# ATSAMS70J20B device description
Architecture: CORTEX-M7; Family: SAMS; Series: SAMS70
Registers are 32-bit, read-write, no defined reset value unless marked. A register's access mark holds for its fields unless they carry their own. Offsets are from the block's base; [hi:lo] are bit positions; {n}, {i} and the like mark numbered series.

## PMC — Power Management Controller
Instances: PMC 0x400E0600
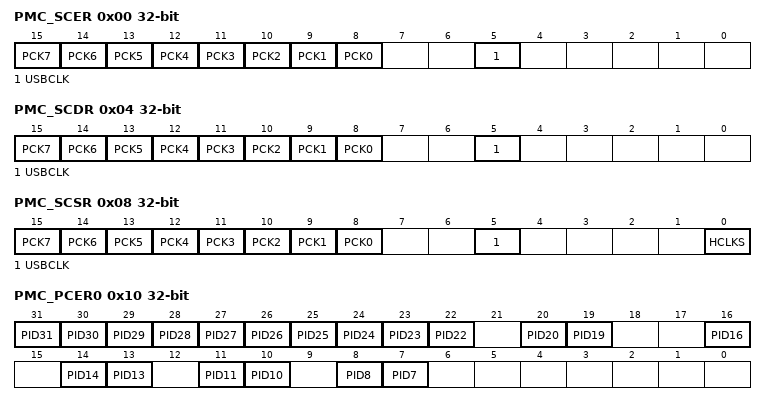
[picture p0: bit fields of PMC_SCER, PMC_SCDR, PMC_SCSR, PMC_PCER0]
0x00 PMC_SCER wo (atomic set of PMC_SCSR) — System Clock Enable Register
  [n+8] PCK{n} (n=0..7) — Programmable Clock {n} Output Enable
  [5] USBCLK — Enable USB FS Clock
0x04 PMC_SCDR wo (atomic clear of PMC_SCSR) — System Clock Disable Register
  [n+8] PCK{n} (n=0..7) — Programmable Clock {n} Output Disable
  [5] USBCLK — Disable USB FS Clock
0x08 PMC_SCSR ro — System Clock Status Register
  [n+8] PCK{n} (n=0..7) — Programmable Clock {n} Output Status
  [5] USBCLK — USB FS Clock Status
  [0] HCLKS — HCLK Status
0x10 PMC_PCER0 wo (atomic set of PMC_PCSR0) — Peripheral Clock Enable Register 0
  [n] PID{n} (n=22..31) — Peripheral Clock {n} Enable
  [20] PID20 — Peripheral Clock 20 Enable
  [19] PID19 — Peripheral Clock 19 Enable
  [16] PID16 — Peripheral Clock 16 Enable
  [14] PID14 — Peripheral Clock 14 Enable
  [13] PID13 — Peripheral Clock 13 Enable
  [11] PID11 — Peripheral Clock 11 Enable
  [10] PID10 — Peripheral Clock 10 Enable
  [8] PID8 — Peripheral Clock 8 Enable
  [7] PID7 — Peripheral Clock 7 Enable
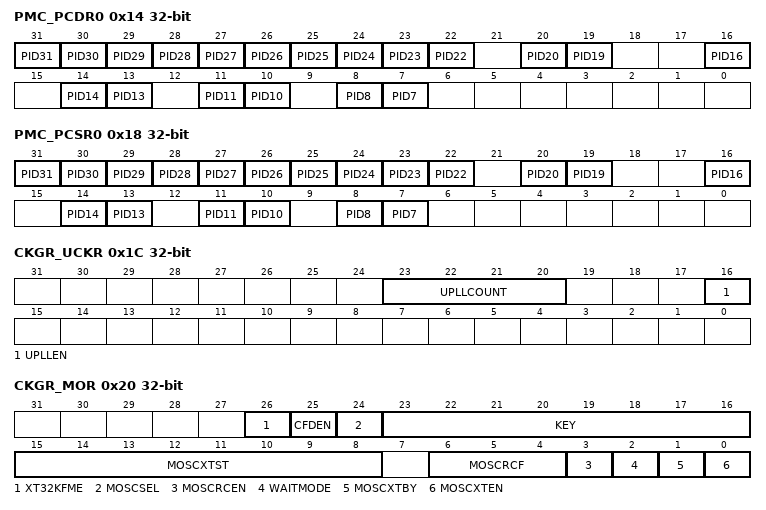
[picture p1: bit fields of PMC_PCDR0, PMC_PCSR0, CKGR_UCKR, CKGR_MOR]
0x14 PMC_PCDR0 wo (atomic clear of PMC_PCSR0) — Peripheral Clock Disable Register 0
  [n] PID{n} (n=22..31) — Peripheral Clock {n} Disable
  [20] PID20 — Peripheral Clock 20 Disable
  [19] PID19 — Peripheral Clock 19 Disable
  [16] PID16 — Peripheral Clock 16 Disable
  [14] PID14 — Peripheral Clock 14 Disable
  [13] PID13 — Peripheral Clock 13 Disable
  [11] PID11 — Peripheral Clock 11 Disable
  [10] PID10 — Peripheral Clock 10 Disable
  [8] PID8 — Peripheral Clock 8 Disable
  [7] PID7 — Peripheral Clock 7 Disable
0x18 PMC_PCSR0 ro — Peripheral Clock Status Register 0
  [n] PID{n} (n=22..31) — Peripheral Clock {n} Status
  [20] PID20 — Peripheral Clock 20 Status
  [19] PID19 — Peripheral Clock 19 Status
  [16] PID16 — Peripheral Clock 16 Status
  [14] PID14 — Peripheral Clock 14 Status
  [13] PID13 — Peripheral Clock 13 Status
  [11] PID11 — Peripheral Clock 11 Status
  [10] PID10 — Peripheral Clock 10 Status
  [8] PID8 — Peripheral Clock 8 Status
  [7] PID7 — Peripheral Clock 7 Status
0x1C CKGR_UCKR — UTMI Clock Register
  [23:20] UPLLCOUNT — UTMI PLL Start-up Time
  [16] UPLLEN — UTMI PLL Enable
0x20 CKGR_MOR — Main Oscillator Register
  [26] XT32KFME — 32.768 kHz Crystal Oscillator Frequency Monitoring Enable
  [25] CFDEN — Clock Failure Detector Enable
  [24] MOSCSEL — Main Clock Oscillator Selection
  [23:16] KEY — Write Access Password
    55=PASSWD (Writing any other value in this field aborts the write operation.Always reads as 0.)
  [15:8] MOSCXTST — Main Crystal Oscillator Startup Time
  [6:4] MOSCRCF — Main RC Oscillator Frequency Selection
    0=_4_MHz (The RC oscillator frequency is at 4 MHz); 1=_8_MHz (The RC oscillator frequency is at 8 MHz); 2=_12_MHz (The RC oscillator frequency is at 12 MHz)
  [3] MOSCRCEN — Main RC Oscillator Enable
  [2] WAITMODE — Wait Mode Command (Write-only)
  [1] MOSCXTBY — Main Crystal Oscillator Bypass
  [0] MOSCXTEN — Main Crystal Oscillator Enable
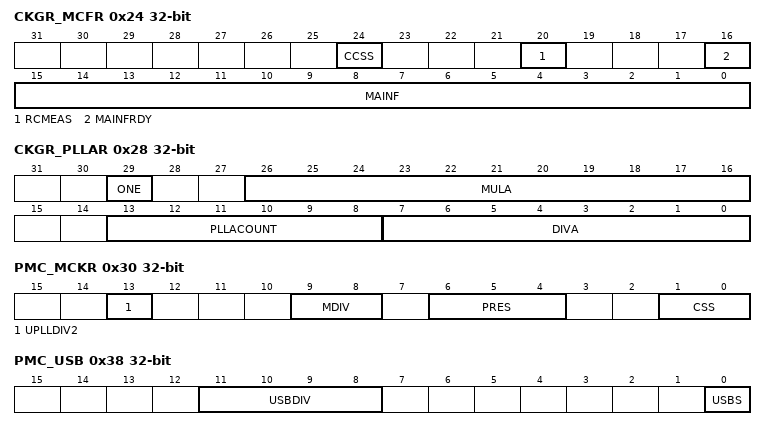
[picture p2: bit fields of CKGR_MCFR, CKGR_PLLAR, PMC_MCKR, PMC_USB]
0x24 CKGR_MCFR — Main Clock Frequency Register
  [24] CCSS — Counter Clock Source Selection
  [20] RCMEAS — RC Oscillator Frequency Measure (write-only)
  [16] MAINFRDY — Main Clock Frequency Measure Ready
  [15:0] MAINF — Main Clock Frequency
0x28 CKGR_PLLAR — PLLA Register
  [29] ONE — Must Be Set to 1
  [26:16] MULA — PLLA Multiplier
  [13:8] PLLACOUNT — PLLA Counter
  [7:0] DIVA — PLLA Front End Divider
    0=Divider output is 0 and PLLA is disabled; 1=BYPASS (Divider is bypassed (divide by 1) and PLLA is enabled.)
0x30 PMC_MCKR — Master Clock Register
  [13] UPLLDIV2 — UPLL Divider by 2
  [9:8] MDIV — Master Clock Division
    0=EQ_PCK (Master Clock is Prescaler Output Clock divided by 1.); 1=PCK_DIV2 (Master Clock is Prescaler Output Clock divided by 2.); 2=PCK_DIV4 (Master Clock is Prescaler Output Clock divided by 4.); 3=PCK_DIV3 (Master Clock is Prescaler Output Clock divided by 3.)
  [6:4] PRES — Processor Clock Prescaler
    0=CLK_1 (Selected clock); 1=CLK_2 (Selected clock divided by 2); 2=CLK_4 (Selected clock divided by 4); 3=CLK_8 (Selected clock divided by 8); 4=CLK_16 (Selected clock divided by 16); 5=CLK_32 (Selected clock divided by 32); 6=CLK_64 (Selected clock divided by 64); 7=CLK_3 (Selected clock divided by 3)
  [1:0] CSS — Master Clock Source Selection
    0=SLOW_CLK (Slow Clock is selected); 1=MAIN_CLK (Main Clock is selected); 2=PLLA_CLK (PLLA Clock is selected); 3=UPLL_CLK (Divided UPLL Clock is selected)
0x38 PMC_USB — USB Clock Register
  [11:8] USBDIV — Divider for USB_48M
  [0] USBS — USB Input Clock Selection
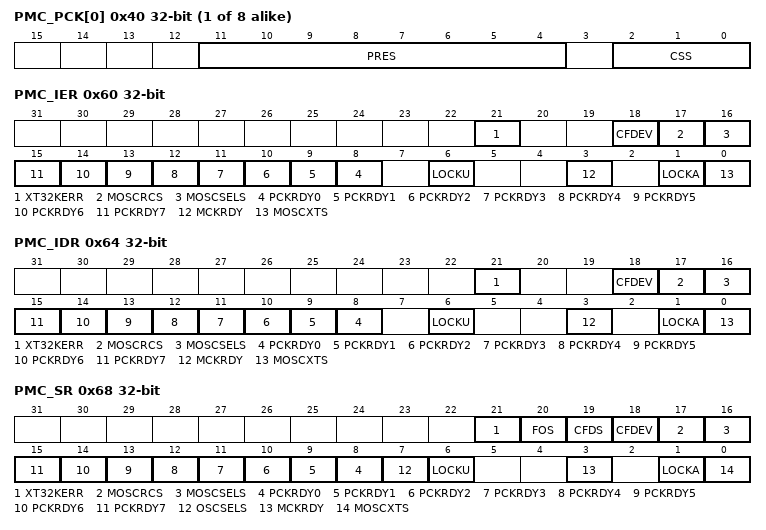
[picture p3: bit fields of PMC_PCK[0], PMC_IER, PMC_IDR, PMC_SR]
{0x40+4i} PMC_PCK[{i}] (i=0..7) — Programmable Clock Register
  [11:4] PRES — Programmable Clock Prescaler
  [2:0] CSS — Programmable Clock Source Selection
    0=SLOW_CLK (SLCK is selected); 1=MAIN_CLK (MAINCK is selected); 2=PLLA_CLK (PLLACK is selected); 3=UPLL_CLK (UPLLCKDIV is selected); 4=MCK (MCK is selected)
0x60 PMC_IER wo (atomic set of PMC_IMR) — Interrupt Enable Register
  [21] XT32KERR — 32.768 kHz Crystal Oscillator Error Interrupt Enable
  [18] CFDEV — Clock Failure Detector Event Interrupt Enable
  [17] MOSCRCS — Main RC Oscillator Status Interrupt Enable
  [16] MOSCSELS — Main Clock Source Oscillator Selection Status Interrupt Enable
  [n+8] PCKRDY{n} (n=0..7) — Programmable Clock Ready {n} Interrupt Enable
  [6] LOCKU — UTMI PLL Lock Interrupt Enable
  [3] MCKRDY — Master Clock Ready Interrupt Enable
  [1] LOCKA — PLLA Lock Interrupt Enable
  [0] MOSCXTS — Main Crystal Oscillator Status Interrupt Enable
0x64 PMC_IDR wo (atomic clear of PMC_IMR) — Interrupt Disable Register
  [21] XT32KERR — 32.768 kHz Crystal Oscillator Error Interrupt Disable
  [18] CFDEV — Clock Failure Detector Event Interrupt Disable
  [17] MOSCRCS — Main RC Status Interrupt Disable
  [16] MOSCSELS — Main Clock Source Oscillator Selection Status Interrupt Disable
  [n+8] PCKRDY{n} (n=0..7) — Programmable Clock Ready {n} Interrupt Disable
  [6] LOCKU — UTMI PLL Lock Interrupt Disable
  [3] MCKRDY — Master Clock Ready Interrupt Disable
  [1] LOCKA — PLLA Lock Interrupt Disable
  [0] MOSCXTS — Main Crystal Oscillator Status Interrupt Disable
0x68 PMC_SR ro — Status Register
  [21] XT32KERR — Slow Crystal Oscillator Error
  [20] FOS — Clock Failure Detector Fault Output Status
  [19] CFDS — Clock Failure Detector Status
  [18] CFDEV — Clock Failure Detector Event
  [17] MOSCRCS — Main RC Oscillator Status
  [16] MOSCSELS — Main Clock Source Oscillator Selection Status
  [n+8] PCKRDY{n} (n=0..7) — Programmable Clock Ready {n} Status
  [7] OSCSELS — Slow Clock Source Oscillator Selection
  [6] LOCKU — UTMI PLL Lock Status
  [3] MCKRDY — Master Clock Status
  [1] LOCKA — PLLA Lock Status
  [0] MOSCXTS — Main Crystal Oscillator Status
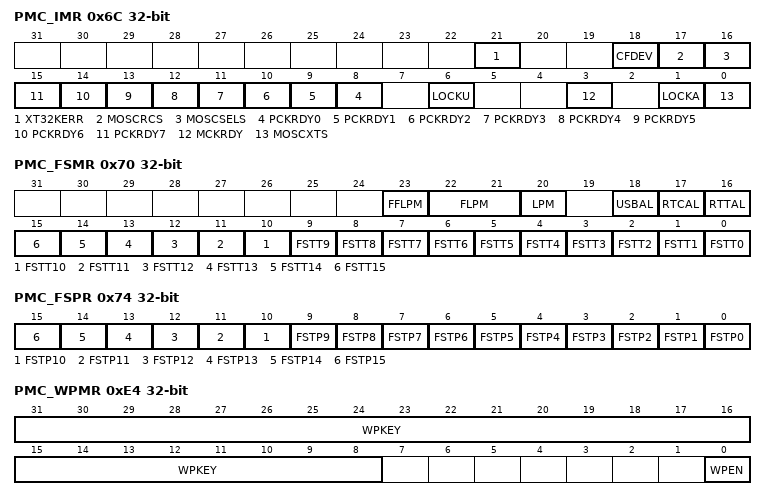
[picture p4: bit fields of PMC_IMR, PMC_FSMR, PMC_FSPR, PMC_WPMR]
0x6C PMC_IMR ro (atomic read) — Interrupt Mask Register
  [21] XT32KERR — 32.768 kHz Crystal Oscillator Error Interrupt Mask
  [18] CFDEV — Clock Failure Detector Event Interrupt Mask
  [17] MOSCRCS — Main RC Status Interrupt Mask
  [16] MOSCSELS — Main Clock Source Oscillator Selection Status Interrupt Mask
  [n+8] PCKRDY{n} (n=0..7) — Programmable Clock Ready {n} Interrupt Mask
  [6] LOCKU — UTMI PLL Lock Interrupt Mask
  [3] MCKRDY — Master Clock Ready Interrupt Mask
  [1] LOCKA — PLLA Lock Interrupt Mask
  [0] MOSCXTS — Main Crystal Oscillator Status Interrupt Mask
0x70 PMC_FSMR — Fast Startup Mode Register
  [23] FFLPM — Force Flash Low-power Mode
  [22:21] FLPM — Flash Low-power Mode
    0=FLASH_STANDBY (Flash is in Standby Mode when system enters Wait Mode); 1=FLASH_DEEP_POWERDOWN (Flash is in Deep-power-down mode when system enters Wait Mode); 2=FLASH_IDLE (Idle mode)
  [20] LPM — Low-power Mode
  [18] USBAL — USB Alarm Enable
  [17] RTCAL — RTC Alarm Enable
  [16] RTTAL — RTT Alarm Enable
  [n] FSTT{n} (n=0..15) — Fast Startup Input Enable {n}
0x74 PMC_FSPR — Fast Startup Polarity Register
  [n] FSTP{n} (n=0..15) — Fast Startup Input Polarity {n}
0x78 PMC_FOCR wo — Fault Output Clear Register
  [0] FOCLR — Fault Output Clear
0xE4 PMC_WPMR — Write Protection Mode Register
  [31:8] WPKEY — Write Protection Key
    0x504D43=PASSWD (Writing any other value in this field aborts the write operation of the WPEN bit. Always reads as 0.)
  [0] WPEN — Write Protection Enable
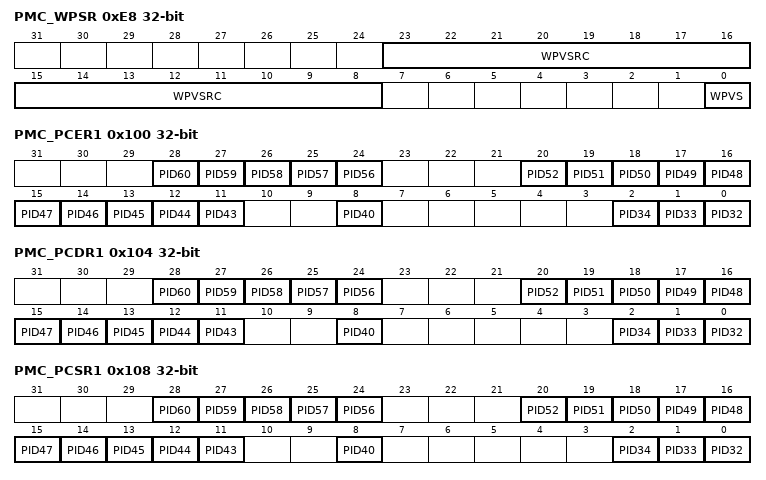
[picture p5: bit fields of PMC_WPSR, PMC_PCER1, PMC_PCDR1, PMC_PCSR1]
0xE8 PMC_WPSR ro — Write Protection Status Register
  [23:8] WPVSRC — Write Protection Violation Source
  [0] WPVS — Write Protection Violation Status
0x100 PMC_PCER1 wo (atomic set of PMC_PCSR1) — Peripheral Clock Enable Register 1
  [n-32] PID{n} (n=56..60) — Peripheral Clock {n} Enable
  [n-32] PID{n} (n=43..52) — Peripheral Clock {n} Enable
  [8] PID40 — Peripheral Clock 40 Enable
  [2] PID34 — Peripheral Clock 34 Enable
  [1] PID33 — Peripheral Clock 33 Enable
  [0] PID32 — Peripheral Clock 32 Enable
0x104 PMC_PCDR1 wo (atomic clear of PMC_PCSR1) — Peripheral Clock Disable Register 1
  [n-32] PID{n} (n=56..60) — Peripheral Clock {n} Disable
  [n-32] PID{n} (n=43..52) — Peripheral Clock {n} Disable
  [8] PID40 — Peripheral Clock 40 Disable
  [2] PID34 — Peripheral Clock 34 Disable
  [1] PID33 — Peripheral Clock 33 Disable
  [0] PID32 — Peripheral Clock 32 Disable
0x108 PMC_PCSR1 ro — Peripheral Clock Status Register 1
  [n-32] PID{n} (n=56..60) — Peripheral Clock {n} Status
  [n-32] PID{n} (n=43..52) — Peripheral Clock {n} Status
  [8] PID40 — Peripheral Clock 40 Status
  [2] PID34 — Peripheral Clock 34 Status
  [1] PID33 — Peripheral Clock 33 Status
  [0] PID32 — Peripheral Clock 32 Status
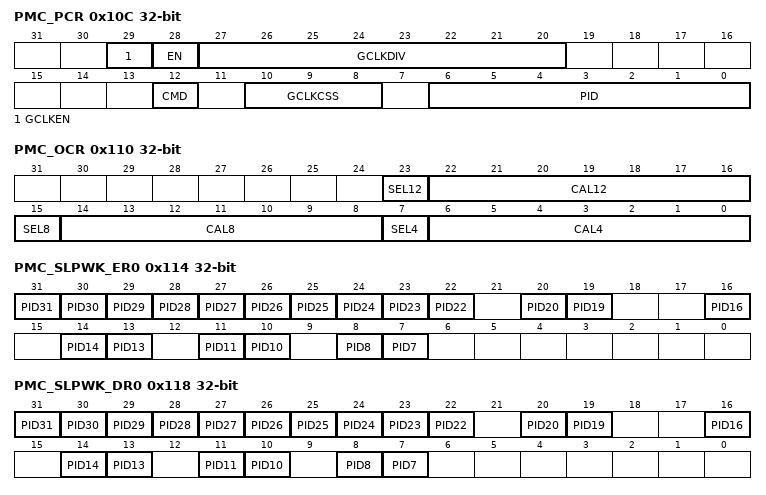
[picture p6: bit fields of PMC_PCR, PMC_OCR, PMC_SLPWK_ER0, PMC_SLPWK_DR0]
0x10C PMC_PCR — Peripheral Control Register
  [29] GCLKEN — Generic Clock Enable
  [28] EN — Enable
  [27:20] GCLKDIV — Generic Clock Division Ratio
  [12] CMD — Command
  [10:8] GCLKCSS — Generic Clock Source Selection
    0=SLOW_CLK (Slow clock is selected); 1=MAIN_CLK (Main clock is selected); 2=PLLA_CLK (PLLACK is selected); 3=UPLL_CLK (UPLL Clock is selected); 4=MCK_CLK (Master Clock is selected)
  [6:0] PID — Peripheral ID
0x110 PMC_OCR — Oscillator Calibration Register
  [23] SEL12 — Selection of Main RC Oscillator Calibration Bits for 12 MHz
  [22:16] CAL12 — Main RC Oscillator Calibration Bits for 12 MHz
  [15] SEL8 — Selection of Main RC Oscillator Calibration Bits for 8 MHz
  [14:8] CAL8 — Main RC Oscillator Calibration Bits for 8 MHz
  [7] SEL4 — Selection of Main RC Oscillator Calibration Bits for 4 MHz
  [6:0] CAL4 — Main RC Oscillator Calibration Bits for 4 MHz
0x114 PMC_SLPWK_ER0 wo (atomic set of PMC_SLPWK_SR0) — SleepWalking Enable Register 0
  [n] PID{n} (n=22..31) — Peripheral {n} SleepWalking Enable
  [20] PID20 — Peripheral 20 SleepWalking Enable
  [19] PID19 — Peripheral 19 SleepWalking Enable
  [16] PID16 — Peripheral 16 SleepWalking Enable
  [14] PID14 — Peripheral 14 SleepWalking Enable
  [13] PID13 — Peripheral 13 SleepWalking Enable
  [11] PID11 — Peripheral 11 SleepWalking Enable
  [10] PID10 — Peripheral 10 SleepWalking Enable
  [8] PID8 — Peripheral 8 SleepWalking Enable
  [7] PID7 — Peripheral 7 SleepWalking Enable
0x118 PMC_SLPWK_DR0 wo (atomic clear of PMC_SLPWK_SR0) — SleepWalking Disable Register 0
  [n] PID{n} (n=22..31) — Peripheral {n} SleepWalking Disable
  [20] PID20 — Peripheral 20 SleepWalking Disable
  [19] PID19 — Peripheral 19 SleepWalking Disable
  [16] PID16 — Peripheral 16 SleepWalking Disable
  [14] PID14 — Peripheral 14 SleepWalking Disable
  [13] PID13 — Peripheral 13 SleepWalking Disable
  [11] PID11 — Peripheral 11 SleepWalking Disable
  [10] PID10 — Peripheral 10 SleepWalking Disable
  [8] PID8 — Peripheral 8 SleepWalking Disable
  [7] PID7 — Peripheral 7 SleepWalking Disable
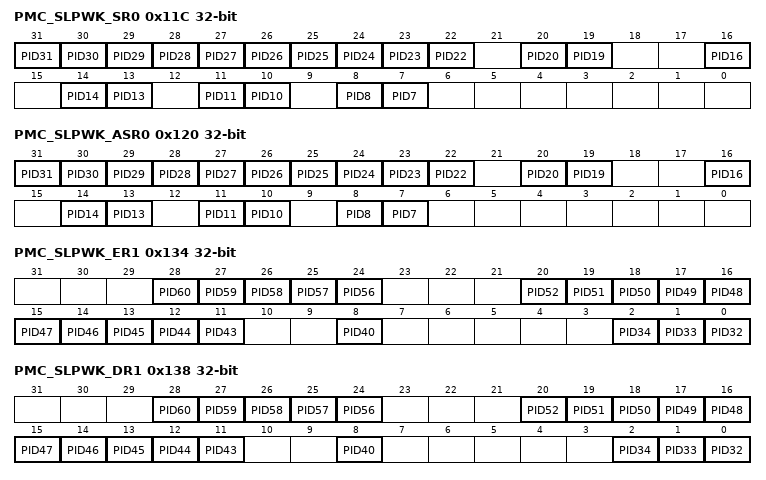
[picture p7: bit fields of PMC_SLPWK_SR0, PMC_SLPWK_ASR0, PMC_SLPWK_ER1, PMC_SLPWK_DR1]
0x11C PMC_SLPWK_SR0 ro — SleepWalking Status Register 0
  [n] PID{n} (n=22..31) — Peripheral {n} SleepWalking Status
  [20] PID20 — Peripheral 20 SleepWalking Status
  [19] PID19 — Peripheral 19 SleepWalking Status
  [16] PID16 — Peripheral 16 SleepWalking Status
  [14] PID14 — Peripheral 14 SleepWalking Status
  [13] PID13 — Peripheral 13 SleepWalking Status
  [11] PID11 — Peripheral 11 SleepWalking Status
  [10] PID10 — Peripheral 10 SleepWalking Status
  [8] PID8 — Peripheral 8 SleepWalking Status
  [7] PID7 — Peripheral 7 SleepWalking Status
0x120 PMC_SLPWK_ASR0 ro — SleepWalking Activity Status Register 0
  [n] PID{n} (n=22..31) — Peripheral {n} Activity Status
  [20] PID20 — Peripheral 20 Activity Status
  [19] PID19 — Peripheral 19 Activity Status
  [16] PID16 — Peripheral 16 Activity Status
  [14] PID14 — Peripheral 14 Activity Status
  [13] PID13 — Peripheral 13 Activity Status
  [11] PID11 — Peripheral 11 Activity Status
  [10] PID10 — Peripheral 10 Activity Status
  [8] PID8 — Peripheral 8 Activity Status
  [7] PID7 — Peripheral 7 Activity Status
0x130 PMC_PMMR — PLL Maximum Multiplier Value Register
  [10:0] PLLA_MMAX — PLLA Maximum Allowed Multiplier Value
0x134 PMC_SLPWK_ER1 wo (atomic set of PMC_SLPWK_SR1) — SleepWalking Enable Register 1
  [n-32] PID{n} (n=56..60) — Peripheral {n} SleepWalking Enable
  [n-32] PID{n} (n=43..52) — Peripheral {n} SleepWalking Enable
  [8] PID40 — Peripheral 40 SleepWalking Enable
  [2] PID34 — Peripheral 34 SleepWalking Enable
  [1] PID33 — Peripheral 33 SleepWalking Enable
  [0] PID32 — Peripheral 32 SleepWalking Enable
0x138 PMC_SLPWK_DR1 wo (atomic clear of PMC_SLPWK_SR1) — SleepWalking Disable Register 1
  [n-32] PID{n} (n=56..60) — Peripheral {n} SleepWalking Disable
  [n-32] PID{n} (n=43..52) — Peripheral {n} SleepWalking Disable
  [8] PID40 — Peripheral 40 SleepWalking Disable
  [2] PID34 — Peripheral 34 SleepWalking Disable
  [1] PID33 — Peripheral 33 SleepWalking Disable
  [0] PID32 — Peripheral 32 SleepWalking Disable
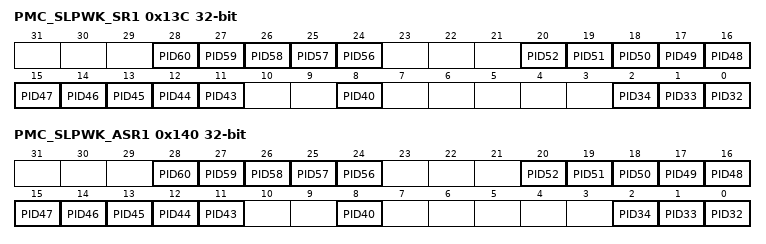
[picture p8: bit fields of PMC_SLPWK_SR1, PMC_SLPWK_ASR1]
0x13C PMC_SLPWK_SR1 ro — SleepWalking Status Register 1
  [n-32] PID{n} (n=56..60) — Peripheral {n} SleepWalking Status
  [n-32] PID{n} (n=43..52) — Peripheral {n} SleepWalking Status
  [8] PID40 — Peripheral 40 SleepWalking Status
  [2] PID34 — Peripheral 34 SleepWalking Status
  [1] PID33 — Peripheral 33 SleepWalking Status
  [0] PID32 — Peripheral 32 SleepWalking Status
0x140 PMC_SLPWK_ASR1 ro — SleepWalking Activity Status Register 1
  [n-32] PID{n} (n=56..60) — Peripheral {n} Activity Status
  [n-32] PID{n} (n=43..52) — Peripheral {n} Activity Status
  [8] PID40 — Peripheral 40 Activity Status
  [2] PID34 — Peripheral 34 Activity Status
  [1] PID33 — Peripheral 33 Activity Status
  [0] PID32 — Peripheral 32 Activity Status
0x144 PMC_SLPWK_AIPR ro — SleepWalking Activity In Progress Register
  [0] AIP — Activity In Progress

## Notices in the file
Copyright (c) 2017 Microchip Technology Inc.
SPDX-License-Identifier: Apache-2.0
Licensed under the Apache License, Version 2.0 (the "License");
you may not use this file except in compliance with the License.
You may obtain a copy of the License at
http://www.apache.org/licenses/LICENSE-2.0
Unless required by applicable law or agreed to in writing, software
distributed under the License is distributed on an "AS IS" BASIS,
WITHOUT WARRANTIES OR CONDITIONS OF ANY KIND, either express or implied.
See the License for the specific language governing permissions and
limitations under the License.
